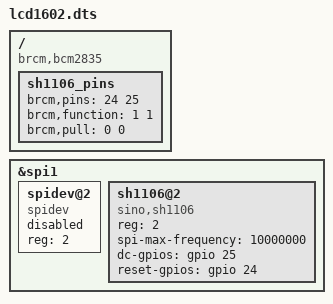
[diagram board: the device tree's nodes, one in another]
/dts-v1/;
/plugin/;

/ {
    compatible = "brcm,bcm2835";

    fragment@0 {
        target = <&spi1>;
        __overlay__ {
            #address-cells = <1>;
            #size-cells = <0>;
            status = "okay";

            spidev@2 {
                compatible = "spidev";
                reg = <2>; // CE2 (Chip Enable 2)
                status = "disabled";
            };
        };
    };

    fragment@1 {
        target = <&spi1>;
        __overlay__ {
            #address-cells = <1>;
            #size-cells = <0>;

            sh1106@2 {
                compatible = "sino,sh1106";
                reg = <2>; // CE2 (Chip Enable 2)
                spi-max-frequency = <10000000>; // 10 MHz
                dc-gpios = <&gpio 25 0>; // GPIO25 for Data/Command
                reset-gpios = <&gpio 24 0>; // GPIO24 for Reset
                status = "okay";
            };
        };
    };

    fragment@2 {
        target-path = "/";
        __overlay__ {
            sh1106_pins: sh1106_pins {
                brcm,pins = <24 25>; // GPIO24 and GPIO25
                brcm,function = <1 1>; // Set as output
                brcm,pull = <0 0>; // No pull-up or pull-down
            };
        };
    };
};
